# STM32F7x6 register map
File version: 1.6
CPU: CM7 r0p1, little endian, MPU, FPU, 4 interrupt priority bits
Registers are 32-bit, read-write, reset 0x0 unless marked. A register's access mark holds for its fields unless they carry their own. Offsets are from the block's base; [hi:lo] are bit positions; {n}, {i} and the like mark numbered series.

## Ethernet_PTP — Ethernet: Precision time protocol
Base 0x40028700
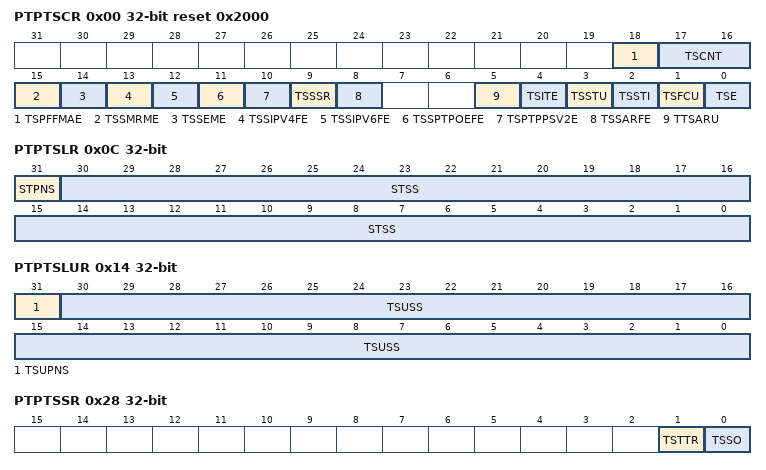
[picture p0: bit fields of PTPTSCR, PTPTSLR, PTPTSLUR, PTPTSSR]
0x00 PTPTSCR reset 0x2000 — Ethernet PTP time stamp control register
  [18] TSPFFMAE, [17:16] TSCNT, [15] TSSMRME, [14] TSSEME, [13] TSSIPV4FE, [12] TSSIPV6FE, [11] TSSPTPOEFE, [10] TSPTPPSV2E, [9] TSSSR, [8] TSSARFE, [5] TTSARU, [4] TSITE, [3] TSSTU, [2] TSSTI, [1] TSFCU, [0] TSE
0x04 PTPSSIR — Ethernet PTP subsecond increment register
  [7:0] STSSI
0x08 PTPTSHR ro — Ethernet PTP time stamp high register
  [31:0] STS
0x0C PTPTSLR ro — Ethernet PTP time stamp low register
  [31] STPNS, [30:0] STSS
0x10 PTPTSHUR — Ethernet PTP time stamp high update register
  [31:0] TSUS
0x14 PTPTSLUR — Ethernet PTP time stamp low update register
  [31] TSUPNS, [30:0] TSUSS
0x18 PTPTSAR — Ethernet PTP time stamp addend register
  [31:0] TSA
0x1C PTPTTHR — Ethernet PTP target time high register
  [31:0] TTSH — 0
0x20 PTPTTLR — Ethernet PTP target time low register
  [31:0] TTSL
0x28 PTPTSSR ro — Ethernet PTP time stamp status register
  [1] TSTTR, [0] TSSO
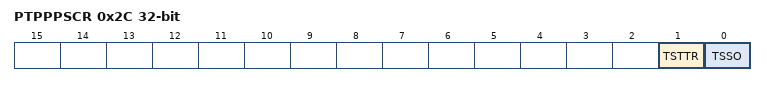
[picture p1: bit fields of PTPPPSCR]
0x2C PTPPPSCR ro — Ethernet PTP PPS control register
  [1] TSTTR, [0] TSSO

## CRC — Cryptographic processor
Base 0x40023000
0x00 DR reset 0xFFFFFFFF — Data register
  [31:0] DR — Data Register
0x00 DR8 8-bit reset 0xFF (alternate view of DR) — Data register - byte sized
  [7:0] DR8 — Data register bits
0x00 DR16 16-bit reset 0xFFFF (alternate view of DR) — Data register - half-word sized
  [15:0] DR16 — Data register bits
0x04 IDR — Independent Data register
  [7:0] IDR
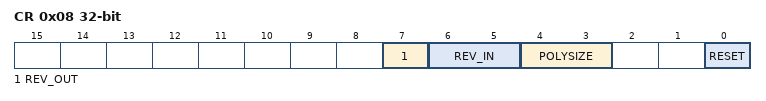
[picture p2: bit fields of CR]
0x08 CR wo — Control register
  [7] REV_OUT rw — Reverse output data
    0=Normal (Bit order not affected); 1=Reversed (Bit reversed output)
  [6:5] REV_IN rw — Reverse input data
    0=Normal (Bit order not affected); 1=Byte (Bit reversal done by byte); 2=HalfWord (Bit reversal done by half-word); 3=Word (Bit reversal done by word)
  [4:3] POLYSIZE rw — Polynomial size
    0=32-bit polynomial; 1=16-bit polynomial; 2=8-bit polynomial; 3=7-bit polynomial
  [0] RESET — RESET bit
    on write: 1=Resets the CRC calculation unit and sets the data register to 0xFFFF FFFF
0x10 INIT — Initial CRC value
  [31:0] INIT — Programmable initial CRC value
0x14 POL — CRC polynomial
  [31:0] POL — Programmable polynomial

## FLASH
Base 0x40023C00
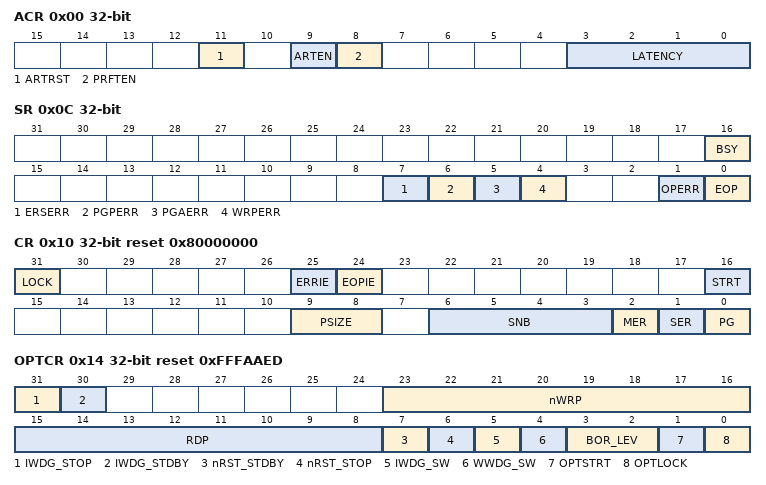
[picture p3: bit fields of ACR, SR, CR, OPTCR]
0x00 ACR — Flash access control register
  [11] ARTRST — ART Accelerator reset
    0=NotReset (Accelerator is not reset); 1=Reset (Accelerator is reset)
  [9] ARTEN — ART Accelerator Enable
    0=Disabled (ART Accelerator is disabled); 1=Enabled (ART Accelerator is enabled)
  [8] PRFTEN — Prefetch enable
    0=Disabled (Prefetch is disabled); 1=Enabled (Prefetch is enabled)
  [3:0] LATENCY
    {v}=WS{v} ({v} wait states) (v=0..15)
0x04 KEYR wo — Flash key register
  [31:0] KEY — FPEC key
0x08 OPTKEYR wo — Flash option key register
  [31:0] OPTKEYR — Option byte key
0x0C SR access per field — Status register
  [16] BSY ro — Busy
    on read: 0=NotBusy (no Flash memory operation ongoing); 1=Busy (Flash memory operation ongoing)
  [7] ERSERR rw write-1-clears — Programming sequence error
    on write: 1=Clear error flag
  [6] PGPERR rw write-1-clears — Programming parallelism error
    on write: 1=Clear error flag
  [5] PGAERR rw write-1-clears — Programming alignment error
    on write: 1=Clear error flag
  [4] WRPERR rw write-1-clears — Write protection error
    on write: 1=Clear error flag
  [1] OPERR rw write-1-clears — Operation error
    on write: 1=Clear error flag
  [0] EOP rw write-1-clears — End of operation
    on write: 1=Clear error flag
0x10 CR reset 0x80000000 — Control register
  [31] LOCK
    0=Unlocked (FLASH_CR register is unlocked); 1=Locked (FLASH_CR register is locked)
  [25] ERRIE — Error interrupt enable
    0=Disabled (Error interrupt generation disabled); 1=Enabled (Error interrupt generation enabled)
  [24] EOPIE — End of operation interrupt enable
    0=Disabled (End of operation interrupt disabled); 1=Enabled (End of operation interrupt enabled)
  [16] STRT — Start
    1=Start (Trigger an erase operation)
  [9:8] PSIZE — Program size
    0=Program x8; 1=Program x16; 2=Program x32; 3=Program x64
  [6:3] SNB range 0..11 — Sector number
  [2] MER — Mass Erase of sectors 0 to 11
    1=MassErase (Erase activated for all user sectors)
  [1] SER — Sector Erase
    1=SectorErase (Erase activated for selected sector)
  [0] PG — Programming
    1=Program (Flash programming activated)
0x14 OPTCR reset 0xFFFAAED — Flash option control register
  [31] IWDG_STOP — Independent watchdog counter freeze in Stop mode
  [30] IWDG_STDBY — Independent watchdog counter freeze in standby mode
  [23:16] nWRP — Not write protect
  [15:8] RDP — Read protect
  [7] nRST_STDBY — User option bytes
  [6] nRST_STOP — User option bytes
  [5] IWDG_SW — User option bytes
  [4] WWDG_SW — User option bytes
  [3:2] BOR_LEV — BOR reset Level
  [1] OPTSTRT — Option start
  [0] OPTLOCK — Option lock
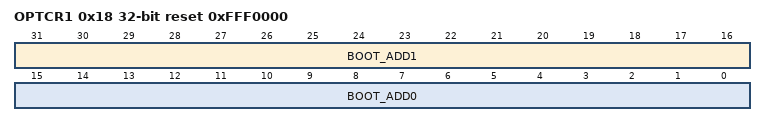
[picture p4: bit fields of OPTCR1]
0x18 OPTCR1 reset 0xFFF0000 — Flash option control register 1
  [31:16] BOOT_ADD1 — Boot base address when Boot pin =1
  [15:0] BOOT_ADD0 — Boot base address when Boot pin =0
